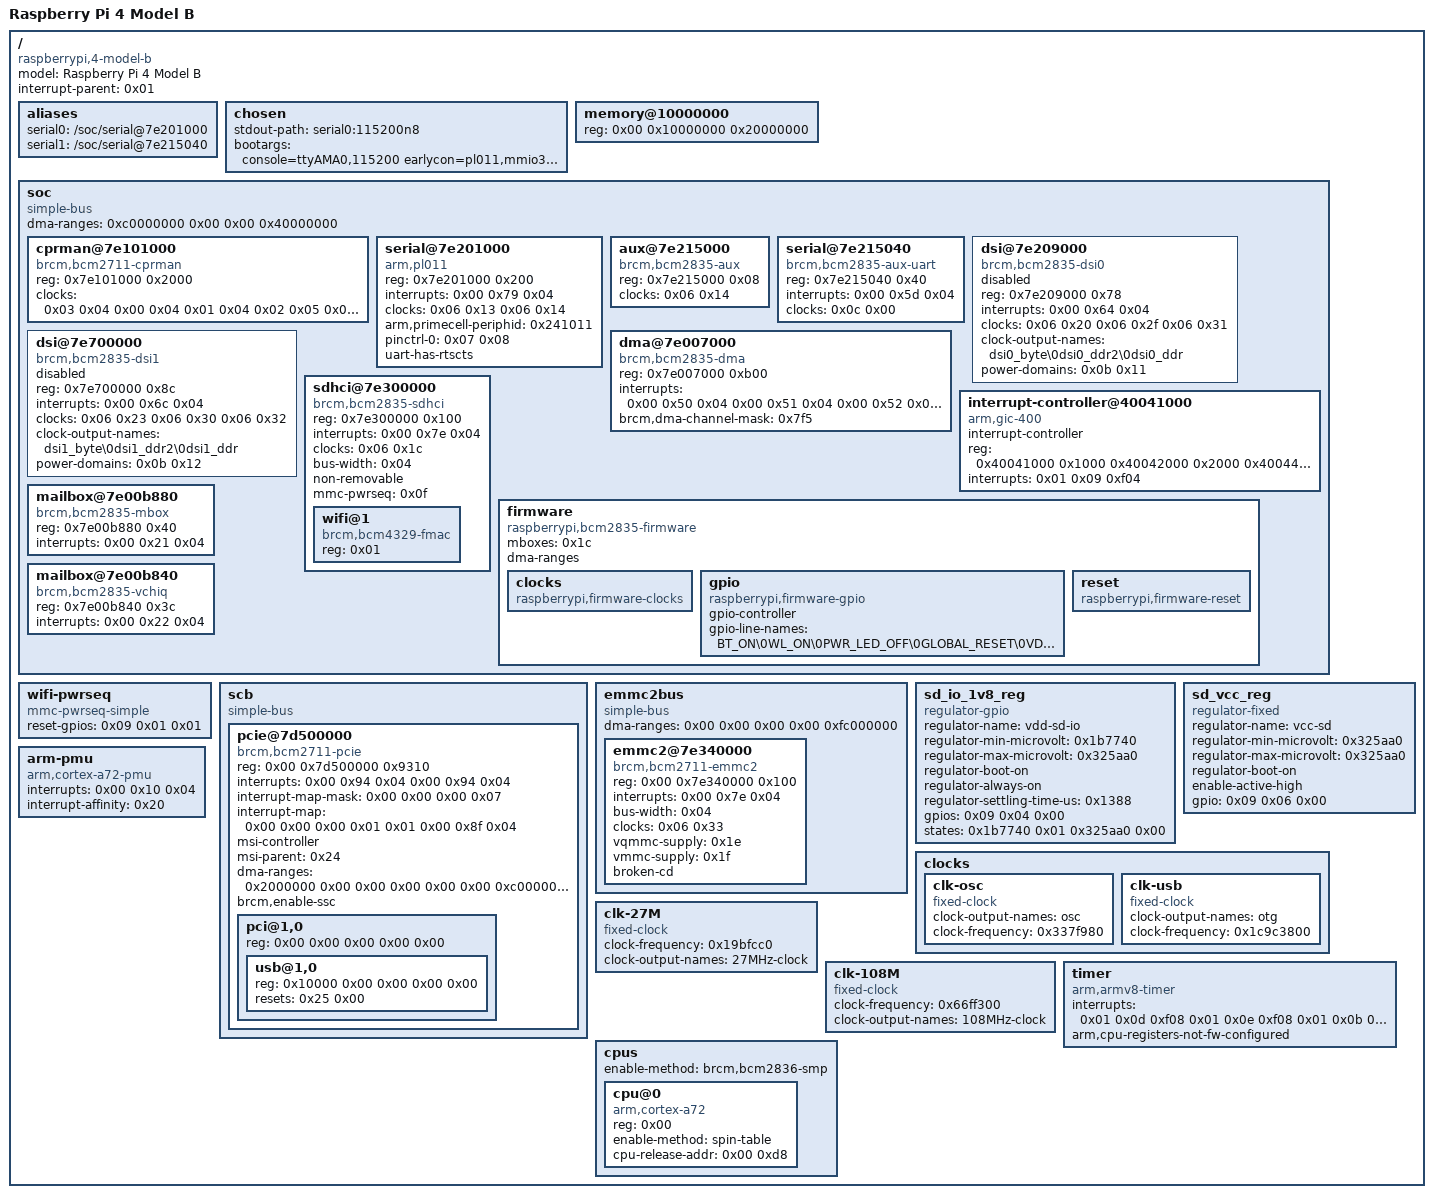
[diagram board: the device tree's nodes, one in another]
/*
 * Copyright Linux Kernel Team
 *
 * SPDX-License-Identifier: GPL-2.0-only
 *
 * This file is derived from an intermediate build stage of the
 * Linux kernel. The licenses of all input files to this process
 * are compatible with GPL-2.0-only.
 */

/dts-v1/;

/memreserve/	0x0000000000000000 0x0000000000001000;
/ {
	compatible = "raspberrypi,4-model-b\0brcm,bcm2711";
	model = "Raspberry Pi 4 Model B";
	#address-cells = <0x02>;
	#size-cells = <0x01>;
	interrupt-parent = <0x01>;

	aliases {
		serial0 = "/soc/serial@7e201000";
		serial1 = "/soc/serial@7e215040";
	};
 
	chosen {
		stdout-path = "serial0:115200n8";
		bootargs = "console=ttyAMA0,115200 earlycon=pl011,mmio32,0xfe201000 debug loglevel=8 root=/dev/mmcblk1p2 rootfstype=ext4 fsck.repair=yes rootwait";
	};

	memory@10000000 {
		device_type = "memory";
		reg = <0x00 0x10000000 0x20000000>;
	};

	soc {
		compatible = "simple-bus";
		#address-cells = <0x01>;
		#size-cells = <0x01>;
		ranges = <0x7e000000 0x00 0xfe000000 0x1800000 0x7c000000 0x00 0xfc000000 0x2000000 0x40000000 0x00 0xff800000 0x800000>;
		dma-ranges = <0xc0000000 0x00 0x00 0x40000000>;

		cprman@7e101000 {
			compatible = "brcm,bcm2711-cprman";
			#clock-cells = <0x01>;
			reg = <0x7e101000 0x2000>;
			clocks = <0x03 0x04 0x00 0x04 0x01 0x04 0x02 0x05 0x00 0x05 0x01 0x05 0x02>;
			phandle = <0x06>;
		};

		serial@7e201000 {
			compatible = "arm,pl011\0arm,primecell";
			reg = <0x7e201000 0x200>;
			interrupts = <0x00 0x79 0x04>;
			clocks = <0x06 0x13 0x06 0x14>;
			clock-names = "uartclk\0apb_pclk";
			arm,primecell-periphid = <0x241011>;
			pinctrl-names = "default";
			pinctrl-0 = <0x07 0x08>;
			uart-has-rtscts;
			status = "okay";

			// bluetooth {
			// 	compatible = "brcm,bcm43438-bt";
			// 	max-speed = <0x1e8480>;
			// 	shutdown-gpios = <0x09 0x00 0x00>;
			// };
		};

		aux@7e215000 {
			compatible = "brcm,bcm2835-aux";
			#clock-cells = <0x01>;
			reg = <0x7e215000 0x08>;
			clocks = <0x06 0x14>;
			phandle = <0x0c>;
		};

		serial@7e215040 {
			compatible = "brcm,bcm2835-aux-uart";
			reg = <0x7e215040 0x40>;
			interrupts = <0x00 0x5d 0x04>;
			clocks = <0x0c 0x00>;
			status = "okay";
		};

		dsi@7e209000 {
			compatible = "brcm,bcm2835-dsi0";
			reg = <0x7e209000 0x78>;
			interrupts = <0x00 0x64 0x04>;
			#address-cells = <0x01>;
			#size-cells = <0x00>;
			#clock-cells = <0x01>;
			clocks = <0x06 0x20 0x06 0x2f 0x06 0x31>;
			clock-names = "phy\0escape\0pixel";
			clock-output-names = "dsi0_byte\0dsi0_ddr2\0dsi0_ddr";
			status = "disabled";
			power-domains = <0x0b 0x11>;
			phandle = <0x04>;
		};

		dsi@7e700000 {
			compatible = "brcm,bcm2835-dsi1";
			reg = <0x7e700000 0x8c>;
			interrupts = <0x00 0x6c 0x04>;
			#address-cells = <0x01>;
			#size-cells = <0x00>;
			#clock-cells = <0x01>;
			clocks = <0x06 0x23 0x06 0x30 0x06 0x32>;
			clock-names = "phy\0escape\0pixel";
			clock-output-names = "dsi1_byte\0dsi1_ddr2\0dsi1_ddr";
			status = "disabled";
			power-domains = <0x0b 0x12>;
			phandle = <0x05>;
		};

		dma@7e007000 {
			compatible = "brcm,bcm2835-dma";
			reg = <0x7e007000 0xb00>;
			interrupts = <0x00 0x50 0x04 0x00 0x51 0x04 0x00 0x52 0x04 0x00 0x53 0x04 0x00 0x54 0x04 0x00 0x55 0x04 0x00 0x56 0x04 0x00 0x57 0x04 0x00 0x57 0x04 0x00 0x58 0x04 0x00 0x58 0x04>;
			interrupt-names = "dma0\0dma1\0dma2\0dma3\0dma4\0dma5\0dma6\0dma7\0dma8\0dma9\0dma10";
			#dma-cells = <0x01>;
			brcm,dma-channel-mask = <0x7f5>;
			phandle = <0x19>;
		};

		interrupt-controller@40041000 {
			interrupt-controller;
			#interrupt-cells = <0x03>;
			compatible = "arm,gic-400";
			reg = <0x40041000 0x1000 0x40042000 0x2000 0x40044000 0x2000 0x40046000 0x2000>;
			interrupts = <0x01 0x09 0xf04>;
			phandle = <0x01>;
		};

		sdhci@7e300000 {
			compatible = "brcm,bcm2835-sdhci";
			reg = <0x7e300000 0x100>;
			interrupts = <0x00 0x7e 0x04>;
			clocks = <0x06 0x1c>;
			status = "okay";
			#address-cells = <0x01>;
			#size-cells = <0x00>;
			bus-width = <0x04>;
			non-removable;
			mmc-pwrseq = <0x0f>;

			wifi@1 {
				reg = <0x01>;
				compatible = "brcm,bcm4329-fmac";
			};
		};

		firmware {
			compatible = "raspberrypi,bcm2835-firmware\0simple-mfd";
			#address-cells = <0x01>;
			#size-cells = <0x01>;
			mboxes = <0x1c>;
			dma-ranges;
			phandle = <0x1d>;

			clocks {
				compatible = "raspberrypi,firmware-clocks";
				#clock-cells = <0x01>;
				phandle = <0x10>;
			};

			gpio {
				compatible = "raspberrypi,firmware-gpio";
				gpio-controller;
				#gpio-cells = <0x02>;
				gpio-line-names = "BT_ON\0WL_ON\0PWR_LED_OFF\0GLOBAL_RESET\0VDD_SD_IO_SEL\0CAM_GPIO\0SD_PWR_ON\0";
				status = "okay";
				phandle = <0x09>;
			};

			reset {
				compatible = "raspberrypi,firmware-reset";
				#reset-cells = <0x01>;
				phandle = <0x25>;
			};
		};

		mailbox@7e00b880 {
			compatible = "brcm,bcm2835-mbox";
			reg = <0x7e00b880 0x40>;
			interrupts = <0x00 0x21 0x04>;
			#mbox-cells = <0x00>;
			phandle = <0x1c>;
		};

		mailbox@7e00b840 {
			compatible = "brcm,bcm2835-vchiq";
			reg = <0x7e00b840 0x3c>;
			interrupts = <0x00 0x22 0x04>;
		};

	};

	wifi-pwrseq {
		compatible = "mmc-pwrseq-simple";
		reset-gpios = <0x09 0x01 0x01>;
		phandle = <0x0f>;
	};

	scb {
		compatible = "simple-bus";
		#address-cells = <0x02>;
		#size-cells = <0x01>;
		ranges = <0x00 0x7c000000 0x00 0xfc000000 0x3800000 0x06 0x00 0x06 0x00 0x40000000>;

		pcie@7d500000 {
			compatible = "brcm,bcm2711-pcie";
			reg = <0x00 0x7d500000 0x9310>;
			device_type = "pci";
			#address-cells = <0x03>;
			#interrupt-cells = <0x01>;
			#size-cells = <0x02>;
			interrupts = <0x00 0x94 0x04 0x00 0x94 0x04>;
			interrupt-names = "pcie\0msi";
			interrupt-map-mask = <0x00 0x00 0x00 0x07>;
			interrupt-map = <0x00 0x00 0x00 0x01 0x01 0x00 0x8f 0x04>;
			msi-controller;
			msi-parent = <0x24>;
			ranges = <0x2000000 0x00 0xf8000000 0x06 0x00 0x00 0x4000000>;
			dma-ranges = <0x2000000 0x00 0x00 0x00 0x00 0x00 0xc0000000>;
			brcm,enable-ssc;
			phandle = <0x24>;

			pci@1,0 {
				#address-cells = <0x03>;
				#size-cells = <0x02>;
				ranges;
				reg = <0x00 0x00 0x00 0x00 0x00>;

				usb@1,0 {
					reg = <0x10000 0x00 0x00 0x00 0x00>;
					resets = <0x25 0x00>;
				};
			};
		};
	};

	emmc2bus {
		compatible = "simple-bus";
		#address-cells = <0x02>;
		#size-cells = <0x01>;
		ranges = <0x00 0x7e000000 0x00 0xfe000000 0x1800000>;
		dma-ranges = <0x00 0x00 0x00 0x00 0xfc000000>;

		emmc2@7e340000 {
			compatible = "brcm,bcm2711-emmc2";
			reg = <0x00 0x7e340000 0x100>;
			interrupts = <0x00 0x7e 0x04>;
			bus-width = <0x04>;
			clocks = <0x06 0x33>;
			status = "okay";
			vqmmc-supply = <0x1e>;
			vmmc-supply = <0x1f>;
			broken-cd;
		};
	};

	sd_io_1v8_reg {
		compatible = "regulator-gpio";
		regulator-name = "vdd-sd-io";
		regulator-min-microvolt = <0x1b7740>;
		regulator-max-microvolt = <0x325aa0>;
		regulator-boot-on;
		regulator-always-on;
		regulator-settling-time-us = <0x1388>;
		gpios = <0x09 0x04 0x00>;
		states = <0x1b7740 0x01 0x325aa0 0x00>;
		status = "okay";
		phandle = <0x1e>;
	};

	sd_vcc_reg {
		compatible = "regulator-fixed";
		regulator-name = "vcc-sd";
		regulator-min-microvolt = <0x325aa0>;
		regulator-max-microvolt = <0x325aa0>;
		regulator-boot-on;
		enable-active-high;
		gpio = <0x09 0x06 0x00>;
		phandle = <0x1f>;
	};

	clocks {

		clk-osc {
			compatible = "fixed-clock";
			#clock-cells = <0x00>;
			clock-output-names = "osc";
			clock-frequency = <0x337f980>;
			phandle = <0x03>;
		};

		clk-usb {
			compatible = "fixed-clock";
			#clock-cells = <0x00>;
			clock-output-names = "otg";
			clock-frequency = <0x1c9c3800>;
			phandle = <0x12>;
		};
	};

	clk-27M {
		#clock-cells = <0x00>;
		compatible = "fixed-clock";
		clock-frequency = <0x19bfcc0>;
		clock-output-names = "27MHz-clock";
		phandle = <0x1a>;
	};

	clk-108M {
		#clock-cells = <0x00>;
		compatible = "fixed-clock";
		clock-frequency = <0x66ff300>;
		clock-output-names = "108MHz-clock";
		phandle = <0x16>;
	};

	arm-pmu {
		compatible = "arm,cortex-a72-pmu\0arm,armv8-pmuv3";
		interrupts = <0x00 0x10 0x04>;
		interrupt-affinity = <0x20>;
	};

	timer {
		compatible = "arm,armv8-timer";
		interrupts = <0x01 0x0d 0xf08 0x01 0x0e 0xf08 0x01 0x0b 0xf08 0x01 0x0a 0xf08>;
		arm,cpu-registers-not-fw-configured;
	};

	cpus {
		#address-cells = <0x01>;
		#size-cells = <0x00>;
		enable-method = "brcm,bcm2836-smp";

		cpu@0 {
			device_type = "cpu";
			compatible = "arm,cortex-a72";
			reg = <0x00>;
			enable-method = "spin-table";
			cpu-release-addr = <0x00 0xd8>;
			phandle = <0x20>;
		};
	};
};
